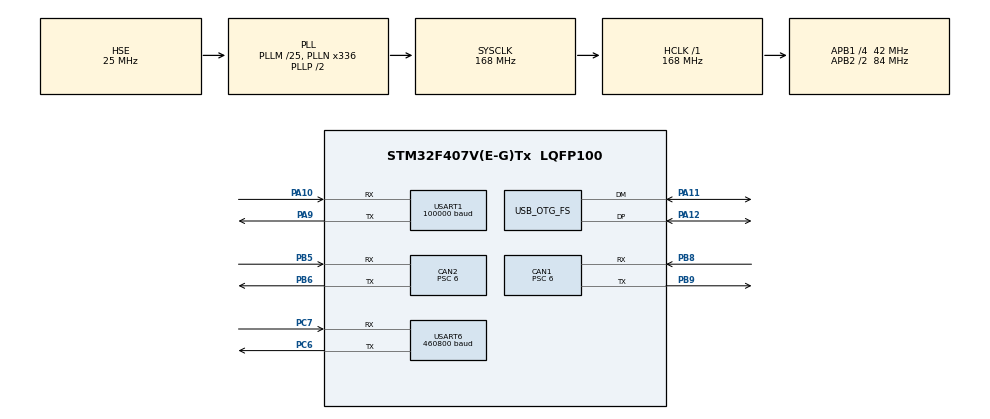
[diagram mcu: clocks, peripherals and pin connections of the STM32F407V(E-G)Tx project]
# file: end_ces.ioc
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CAN1.BS1=CAN_BS1_3TQ
CAN1.BS2=CAN_BS2_3TQ
CAN1.CalculateBaudRate=1000000
CAN1.CalculateTimeBit=1000
CAN1.CalculateTimeQuantum=142.85714285714286
CAN1.Prescaler=6
CAN2.BS1=CAN_BS1_3TQ
CAN2.BS2=CAN_BS2_3TQ
CAN2.CalculateBaudRate=1000000
CAN2.CalculateTimeBit=1000
CAN2.CalculateTimeQuantum=142.85714285714286
CAN2.Prescaler=6
Dma.Request0=USART1_RX
Dma.Request1=USART6_RX
Dma.USART1_RX.0.Direction=DMA_PERIPH_TO_MEMORY
Dma.USART1_RX.0.FIFOMode=DMA_FIFOMODE_DISABLE
Dma.USART1_RX.0.Instance=DMA2_Stream2
Dma.USART1_RX.0.MemDataAlignment=DMA_MDATAALIGN_BYTE
Dma.USART1_RX.0.MemInc=DMA_MINC_ENABLE
Dma.USART1_RX.0.Mode=DMA_NORMAL
Dma.USART1_RX.0.PeriphDataAlignment=DMA_PDATAALIGN_BYTE
Dma.USART1_RX.0.PeriphInc=DMA_PINC_DISABLE
Dma.USART1_RX.0.Priority=DMA_PRIORITY_LOW
Dma.USART6_RX.1.Direction=DMA_PERIPH_TO_MEMORY
Dma.USART6_RX.1.FIFOMode=DMA_FIFOMODE_DISABLE
Dma.USART6_RX.1.Instance=DMA2_Stream1
Dma.USART6_RX.1.MemDataAlignment=DMA_MDATAALIGN_BYTE
Dma.USART6_RX.1.MemInc=DMA_MINC_ENABLE
Dma.USART6_RX.1.Mode=DMA_NORMAL
Dma.USART6_RX.1.PeriphDataAlignment=DMA_PDATAALIGN_BYTE
Dma.USART6_RX.1.PeriphInc=DMA_PINC_DISABLE
Dma.USART6_RX.1.Priority=DMA_PRIORITY_LOW
FREERTOS.BinarySemaphores01=myBinarySem01,Dynamic,NULL
FREERTOS.INCLUDE_eTaskGetState=1
FREERTOS.INCLUDE_vTaskDelayUntil=1
FREERTOS.Tasks01=defaultTask,0,128,StartDefaultTask,Default,NULL,Dynamic,NULL,NULL
Mcu.Family=STM32F4
Mcu.Name=STM32F407V(E-G)Tx
Mcu.Package=LQFP100
NVIC.CAN1_RX0_IRQn=true\:5\:0\:false\:false\:true\:true\:true\:true\:true
NVIC.CAN2_RX1_IRQn=true\:5\:0\:false\:false\:true\:true\:true\:true\:true
NVIC.DMA2_Stream1_IRQn=true\:5\:0\:false\:false\:true\:true\:false\:true\:true
NVIC.DMA2_Stream2_IRQn=true\:5\:0\:false\:false\:true\:true\:false\:true\:true
NVIC.OTG_FS_IRQn=true\:5\:0\:false\:false\:true\:true\:false\:true\:true
NVIC.PriorityGroup=NVIC_PRIORITYGROUP_4
NVIC.TIM1_UP_TIM10_IRQn=true\:5\:0\:false\:false\:true\:true\:true\:true\:true
NVIC.TIM3_IRQn=true\:15\:0\:false\:false\:true\:false\:false\:true\:true
NVIC.TimeBase=TIM3_IRQn
NVIC.TimeBaseIP=TIM3
NVIC.USART1_IRQn=true\:5\:0\:false\:false\:true\:true\:true\:true\:true
NVIC.USART6_IRQn=true\:5\:0\:false\:false\:true\:true\:true\:true\:true
PA10.Mode=Asynchronous
PA10.Signal=USART1_RX
PA11.Mode=Device_Only
PA11.Signal=USB_OTG_FS_DM
PA12.Mode=Device_Only
PA12.Signal=USB_OTG_FS_DP
PA13.Mode=Serial_Wire
PA13.Signal=SYS_JTMS-SWDIO
PA14.Mode=Serial_Wire
PA14.Signal=SYS_JTCK-SWCLK
PA9.Mode=Asynchronous
PA9.Signal=USART1_TX
PB5.Mode=CAN_Activate
PB5.Signal=CAN2_RX
PB6.Mode=CAN_Activate
PB6.Signal=CAN2_TX
PB8.Mode=CAN_Activate
PB8.Signal=CAN1_RX
PB9.Mode=CAN_Activate
PB9.Signal=CAN1_TX
PC6.Mode=Asynchronous
PC6.Signal=USART6_TX
PC7.Mode=Asynchronous
PC7.Signal=USART6_RX
PH0-OSC_IN.Mode=HSE-External-Oscillator
PH0-OSC_IN.Signal=RCC_OSC_IN
PH1-OSC_OUT.Mode=HSE-External-Oscillator
PH1-OSC_OUT.Signal=RCC_OSC_OUT
ProjectManager.HeapSize=0x200
ProjectManager.StackSize=0x400
ProjectManager.TargetToolchain=MDK-ARM V5.32
RCC.48MHZClocksFreq_Value=48000000
RCC.AHBFreq_Value=168000000
RCC.APB1CLKDivider=RCC_HCLK_DIV4
RCC.APB1Freq_Value=42000000
RCC.APB1TimFreq_Value=84000000
RCC.APB2CLKDivider=RCC_HCLK_DIV2
RCC.APB2Freq_Value=84000000
RCC.APB2TimFreq_Value=168000000
RCC.CortexFreq_Value=168000000
RCC.HCLKFreq_Value=168000000
RCC.HSE_VALUE=25000000
RCC.HSI_VALUE=16000000
RCC.LSE_VALUE=32768
RCC.PLLM=25
RCC.PLLN=336
RCC.PLLQ=7
RCC.SYSCLKFreq_VALUE=168000000
RCC.SYSCLKSource=RCC_SYSCLKSOURCE_PLLCLK
RCC.VCOOutputFreq_Value=336000000
TIM1.Period=1999
TIM1.Prescaler=167
TIM5.Period=9
TIM5.Prescaler=167
USART1.BaudRate=100000
USART1.VirtualMode=VM_ASYNC
USART6.BaudRate=460800
USART6.VirtualMode=VM_ASYNC
USB_DEVICE.CLASS_NAME_FS=CDC
USB_DEVICE.VirtualMode-CDC_FS=Cdc
USB_DEVICE.VirtualModeFS=Cdc_FS
USB_OTG_FS.VirtualMode=Device_Only
VP_FREERTOS_VS_CMSIS_V1.Mode=CMSIS_V1
VP_SYS_VS_tim3.Mode=TIM3
VP_TIM1_VS_ClockSourceINT.Mode=Internal
VP_TIM5_VS_ClockSourceINT.Mode=Internal
VP_USB_DEVICE_VS_USB_DEVICE_CDC_FS.Mode=CDC_FS
board=custom

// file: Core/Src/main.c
/* USER CODE BEGIN Header */
/**
  ******************************************************************************
  * @file           : main.c
  * @brief          : Main program body
  ******************************************************************************
  * @attention
  *
  * Copyright (c) 2023 STMicroelectronics.
  * All rights reserved.
  *
  * This software is licensed under terms that can be found in the LICENSE file
  * in the root directory of this software component.
  * If no LICENSE file comes with this software, it is provided AS-IS.
  *
  ******************************************************************************
  */
/* USER CODE END Header */
#include "main.h"
#include "cmsis_os.h"
#include "can.h"
#include "dma.h"
#include "tim.h"
#include "usart.h"
#include "usb_device.h"
#include "gpio.h"

void SystemClock_Config(void);
void MX_FREERTOS_Init(void);

int main(void)
{

  /* MCU Configuration--------------------------------------------------------*/

  /* Reset of all peripherals, Initializes the Flash interface and the Systick. */
  HAL_Init();

  /* Configure the system clock */
  SystemClock_Config();

  /* Initialize all configured peripherals */
  MX_GPIO_Init();
  MX_DMA_Init();
  MX_CAN1_Init();
  MX_CAN2_Init();
  MX_TIM1_Init();
  MX_TIM5_Init();
  MX_USART1_UART_Init();
  MX_USART6_UART_Init();

  /* Call init function for freertos objects (in freertos.c) */
  MX_FREERTOS_Init();

  /* Start scheduler */
  osKernelStart();
  /* We should never get here as control is now taken by the scheduler */
  /* Infinite loop */
  while (1)
  {

  }
}

void SystemClock_Config(void)
{
  RCC_OscInitTypeDef RCC_OscInitStruct = {0};
  RCC_ClkInitTypeDef RCC_ClkInitStruct = {0};

  /** Configure the main internal regulator output voltage
  */
  __HAL_RCC_PWR_CLK_ENABLE();
  __HAL_PWR_VOLTAGESCALING_CONFIG(PWR_REGULATOR_VOLTAGE_SCALE1);

  /** Initializes the RCC Oscillators according to the specified parameters
  * in the RCC_OscInitTypeDef structure.
  */
  RCC_OscInitStruct.OscillatorType = RCC_OSCILLATORTYPE_HSE;
  RCC_OscInitStruct.HSEState = RCC_HSE_ON;
  RCC_OscInitStruct.PLL.PLLState = RCC_PLL_ON;
  RCC_OscInitStruct.PLL.PLLSource = RCC_PLLSOURCE_HSE;
  RCC_OscInitStruct.PLL.PLLM = 25;
  RCC_OscInitStruct.PLL.PLLN = 336;
  RCC_OscInitStruct.PLL.PLLP = RCC_PLLP_DIV2;
  RCC_OscInitStruct.PLL.PLLQ = 7;
  if (HAL_RCC_OscConfig(&RCC_OscInitStruct) != HAL_OK)
  {
    Error_Handler();
  }

  /** Initializes the CPU, AHB and APB buses clocks
  */
  RCC_ClkInitStruct.ClockType = RCC_CLOCKTYPE_HCLK|RCC_CLOCKTYPE_SYSCLK
                              |RCC_CLOCKTYPE_PCLK1|RCC_CLOCKTYPE_PCLK2;
  RCC_ClkInitStruct.SYSCLKSource = RCC_SYSCLKSOURCE_PLLCLK;
  RCC_ClkInitStruct.AHBCLKDivider = RCC_SYSCLK_DIV1;
  RCC_ClkInitStruct.APB1CLKDivider = RCC_HCLK_DIV4;
  RCC_ClkInitStruct.APB2CLKDivider = RCC_HCLK_DIV2;

  if (HAL_RCC_ClockConfig(&RCC_ClkInitStruct, FLASH_LATENCY_5) != HAL_OK)
  {
    Error_Handler();
  }
}

void HAL_TIM_PeriodElapsedCallback(TIM_HandleTypeDef *htim)
{
  if (htim->Instance == TIM3) {
    HAL_IncTick();
  }
}

void Error_Handler(void)
{
  __disable_irq();
  while (1)
  {
  }
}

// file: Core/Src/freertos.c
/* USER CODE BEGIN Header */
/**
  ******************************************************************************
  * File Name          : freertos.c
  * Description        : Code for freertos applications
  ******************************************************************************
  * @attention
  *
  * Copyright (c) 2023 STMicroelectronics.
  * All rights reserved.
  *
  * This software is licensed under terms that can be found in the LICENSE file
  * in the root directory of this software component.
  * If no LICENSE file comes with this software, it is provided AS-IS.
  *
  ******************************************************************************
  */
/* USER CODE END Header */

#include "FreeRTOS.h"
#include "task.h"
#include "main.h"
#include "cmsis_os.h"

/* USER CODE BEGIN Includes */
#include "Task_Init.h"
/* USER CODE END Includes */

osThreadId defaultTaskHandle;
osSemaphoreId myBinarySem01Handle;

void StartDefaultTask(void const * argument);

extern void MX_USB_DEVICE_Init(void);
void MX_FREERTOS_Init(void); /* (MISRA C 2004 rule 8.1) */

/* GetIdleTaskMemory prototype (linked to static allocation support) */
void vApplicationGetIdleTaskMemory( StaticTask_t **ppxIdleTaskTCBBuffer, StackType_t **ppxIdleTaskStackBuffer, uint32_t *pulIdleTaskStackSize );

/* USER CODE BEGIN GET_IDLE_TASK_MEMORY */
static StaticTask_t xIdleTaskTCBBuffer;
static StackType_t xIdleStack[configMINIMAL_STACK_SIZE];

void vApplicationGetIdleTaskMemory( StaticTask_t **ppxIdleTaskTCBBuffer, StackType_t **ppxIdleTaskStackBuffer, uint32_t *pulIdleTaskStackSize )
{
  *ppxIdleTaskTCBBuffer = &xIdleTaskTCBBuffer;
  *ppxIdleTaskStackBuffer = &xIdleStack[0];
  *pulIdleTaskStackSize = configMINIMAL_STACK_SIZE;
  /* place for user code */
}
/* USER CODE END GET_IDLE_TASK_MEMORY */

void MX_FREERTOS_Init(void) {

  /* Create the semaphores(s) */
  /* definition and creation of myBinarySem01 */
  osSemaphoreDef(myBinarySem01);
  myBinarySem01Handle = osSemaphoreCreate(osSemaphore(myBinarySem01), 1);

  /* Create the thread(s) */
  /* definition and creation of defaultTask */
  osThreadDef(defaultTask, StartDefaultTask, osPriorityNormal, 0, 128);
  defaultTaskHandle = osThreadCreate(osThread(defaultTask), NULL);

}

void StartDefaultTask(void const * argument)
{
  /* init code for USB_DEVICE */
  MX_USB_DEVICE_Init();
  /* USER CODE BEGIN StartDefaultTask */
  /* Infinite loop */
  for(;;)
  {
      /* 进临界区 */
    taskENTER_CRITICAL();
    Start_Task();
    /* 出临界区 */
    taskEXIT_CRITICAL();
    /* 删除初始任务 */
    vTaskDelete(NULL);
    osDelay(1);
  }
  /* USER CODE END StartDefaultTask */
}
